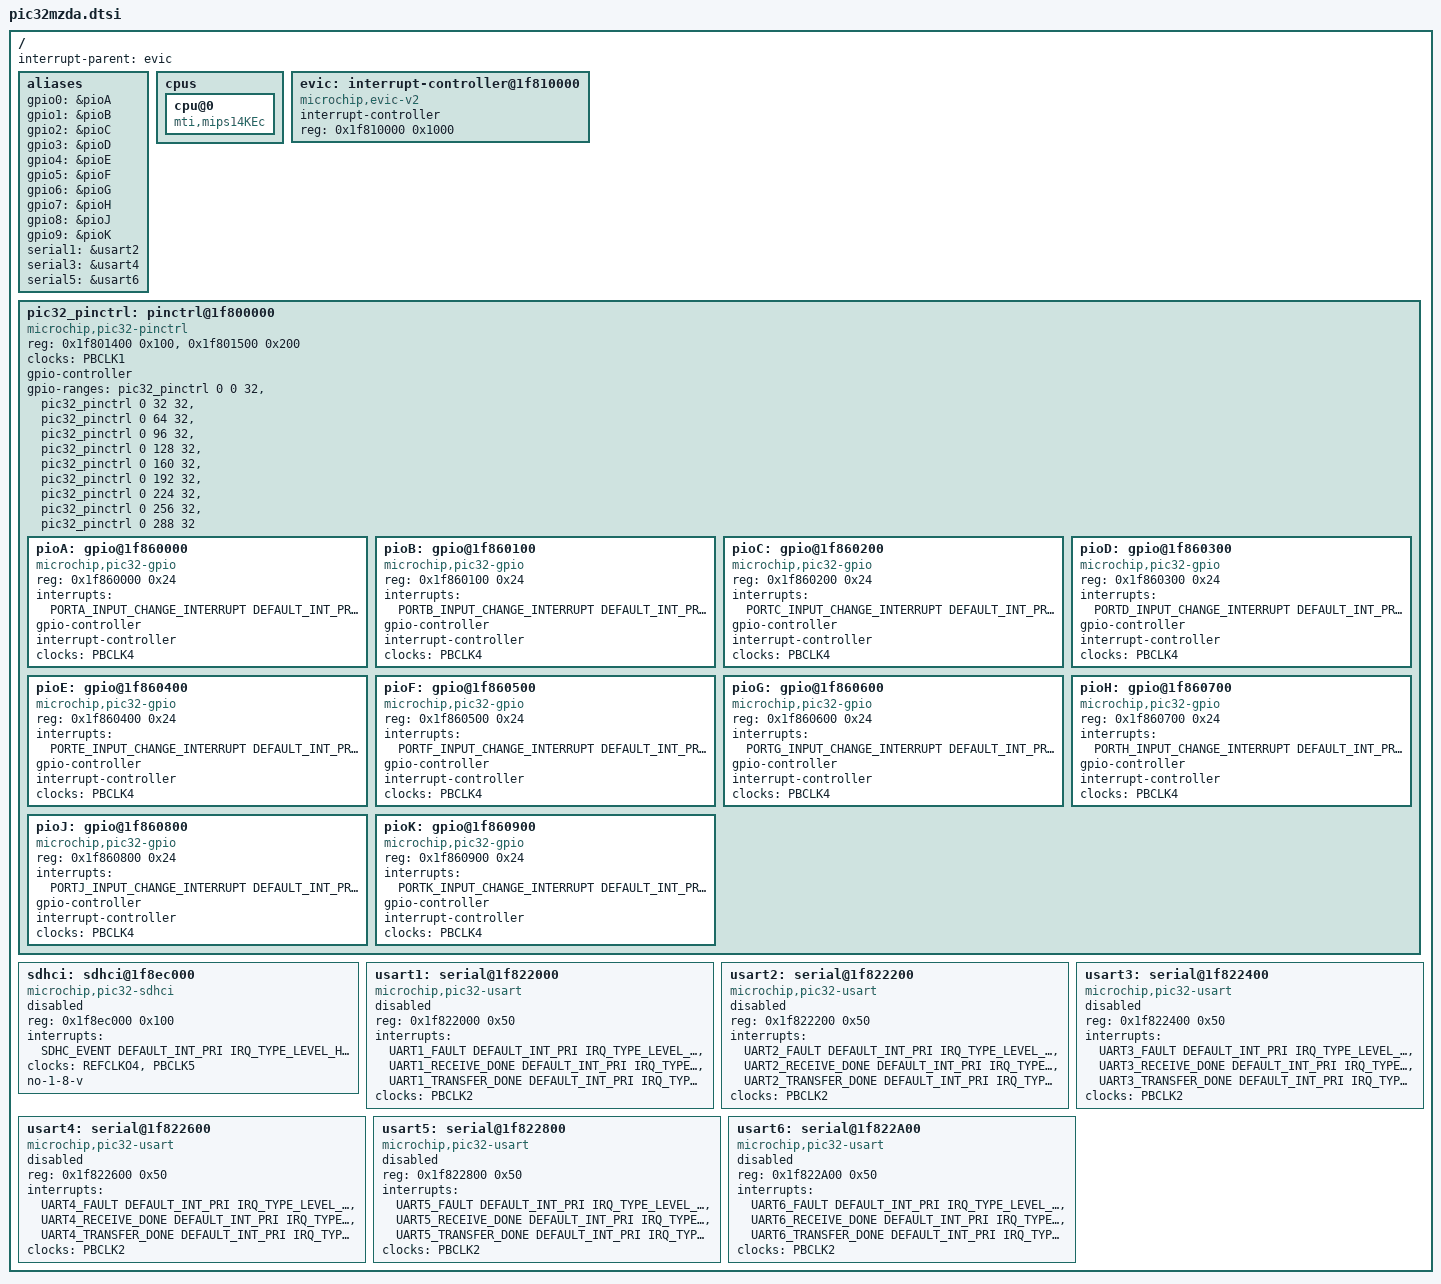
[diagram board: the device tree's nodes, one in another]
/*
 * Copyright (C) 2015 Microchip Technology Inc.  All rights reserved.
 *
 * This program is free software; you can redistribute it and/or modify
 * it under the terms of the GNU General Public License version 2 as
 * published by the Free Software Foundation.
 *
 */

#include <dt-bindings/interrupt-controller/microchip,pic32mz-evic.h>

#include "pic32mzda-clk.dtsi"

/ {
	#address-cells = <1>;
	#size-cells = <1>;
	interrupt-parent = <&evic>;

	aliases {
		gpio0 = &pioA;
		gpio1 = &pioB;
		gpio2 = &pioC;
		gpio3 = &pioD;
		gpio4 = &pioE;
		gpio5 = &pioF;
		gpio6 = &pioG;
		gpio7 = &pioH;
		gpio8 = &pioJ;
		gpio9 = &pioK;
		serial1 = &usart2;
		serial3 = &usart4;
		serial5 = &usart6;
	};

	cpus {
		#address-cells = <1>;
		#size-cells = <0>;

		cpu@0 {
			compatible = "mti,mips14KEc";
			device_type = "cpu";
		};
	};

	evic: interrupt-controller@1f810000 {
		compatible = "microchip,evic-v2";
		interrupt-controller;
		#interrupt-cells = <3>;
		reg = <0x1f810000 0x1000>;
		device_type="evic-v2";
	};

	pic32_pinctrl: pinctrl@1f800000{
		#address-cells = <1>;
		#size-cells = <1>;
		#gpio-range-cells = <3>;
		compatible = "microchip,pic32-pinctrl", "simple-bus";
		ranges;
		reg = <0x1f801400 0x100>, /* in	 */
		      <0x1f801500 0x200>; /* out */
		clocks = <&PBCLK1>;
		gpio-controller;
		#gpio-cells = <2>;
		gpio-ranges = <&pic32_pinctrl 0 0 32
			&pic32_pinctrl 0 32 32
			&pic32_pinctrl 0 64 32
			&pic32_pinctrl 0 96 32
			&pic32_pinctrl 0 128 32
			&pic32_pinctrl 0 160 32
			&pic32_pinctrl 0 192 32
			&pic32_pinctrl 0 224 32
			&pic32_pinctrl 0 256 32
			&pic32_pinctrl 0 288 32>;

		/* GPIO banks */
		pioA: gpio@1f860000 {
			compatible = "microchip,pic32-gpio";
			reg = <0x1f860000 0x24>;
			interrupts = <PORTA_INPUT_CHANGE_INTERRUPT
					DEFAULT_INT_PRI IRQ_TYPE_LEVEL_HIGH>;
			#gpio-cells = <2>;
			gpio-controller;
			interrupt-controller;
			#interrupt-cells = <2>;
			clocks = <&PBCLK4>;
		};

		pioB: gpio@1f860100 {
			compatible = "microchip,pic32-gpio";
			reg = <0x1f860100 0x24>;
			interrupts = <PORTB_INPUT_CHANGE_INTERRUPT
					DEFAULT_INT_PRI IRQ_TYPE_LEVEL_HIGH>;
			#gpio-cells = <2>;
			gpio-controller;
			interrupt-controller;
			#interrupt-cells = <2>;
			clocks = <&PBCLK4>;
		};

		pioC: gpio@1f860200 {
			compatible = "microchip,pic32-gpio";
			reg = <0x1f860200 0x24>;
			interrupts = <PORTC_INPUT_CHANGE_INTERRUPT
					DEFAULT_INT_PRI IRQ_TYPE_LEVEL_HIGH>;
			#gpio-cells = <2>;
			gpio-controller;
			interrupt-controller;
			#interrupt-cells = <2>;
			clocks = <&PBCLK4>;
		};

		pioD: gpio@1f860300 {
			compatible = "microchip,pic32-gpio";
			reg = <0x1f860300 0x24>;
			interrupts = <PORTD_INPUT_CHANGE_INTERRUPT
					DEFAULT_INT_PRI IRQ_TYPE_LEVEL_HIGH>;
			#gpio-cells = <2>;
			gpio-controller;
			interrupt-controller;
			#interrupt-cells = <2>;
			clocks = <&PBCLK4>;
		};

		pioE: gpio@1f860400 {
			compatible = "microchip,pic32-gpio";
			reg = <0x1f860400 0x24>;
			interrupts = <PORTE_INPUT_CHANGE_INTERRUPT
					DEFAULT_INT_PRI IRQ_TYPE_LEVEL_HIGH>;
			#gpio-cells = <2>;
			gpio-controller;
			interrupt-controller;
			#interrupt-cells = <2>;
			clocks = <&PBCLK4>;
		};

		pioF: gpio@1f860500 {
			compatible = "microchip,pic32-gpio";
			reg = <0x1f860500 0x24>;
			interrupts = <PORTF_INPUT_CHANGE_INTERRUPT
					DEFAULT_INT_PRI IRQ_TYPE_LEVEL_HIGH>;
			#gpio-cells = <2>;
			gpio-controller;
			interrupt-controller;
			#interrupt-cells = <2>;
			clocks = <&PBCLK4>;
		};

		pioG: gpio@1f860600 {
			compatible = "microchip,pic32-gpio";
			reg = <0x1f860600 0x24>;
			interrupts = <PORTG_INPUT_CHANGE_INTERRUPT
					 DEFAULT_INT_PRI IRQ_TYPE_LEVEL_HIGH>;
			#gpio-cells = <2>;
			gpio-controller;
			interrupt-controller;
			#interrupt-cells = <2>;
			clocks = <&PBCLK4>;
		};

		pioH: gpio@1f860700 {
			compatible = "microchip,pic32-gpio";
			reg = <0x1f860700 0x24>;
			interrupts = <PORTH_INPUT_CHANGE_INTERRUPT
					DEFAULT_INT_PRI IRQ_TYPE_LEVEL_HIGH>;
			#gpio-cells = <2>;
			gpio-controller;
			interrupt-controller;
			#interrupt-cells = <2>;
			clocks = <&PBCLK4>;
		};

		/* There is no pioI */

		pioJ: gpio@1f860800 {
			compatible = "microchip,pic32-gpio";
			reg = <0x1f860800 0x24>;
			interrupts = <PORTJ_INPUT_CHANGE_INTERRUPT
					DEFAULT_INT_PRI IRQ_TYPE_LEVEL_HIGH>;
			#gpio-cells = <2>;
			gpio-controller;
			interrupt-controller;
			#interrupt-cells = <2>;
			clocks = <&PBCLK4>;
		};

		pioK: gpio@1f860900 {
			compatible = "microchip,pic32-gpio";
			reg = <0x1f860900 0x24>;
			interrupts = <PORTK_INPUT_CHANGE_INTERRUPT
					DEFAULT_INT_PRI IRQ_TYPE_LEVEL_HIGH>;
			#gpio-cells = <2>;
			gpio-controller;
			interrupt-controller;
			#interrupt-cells = <2>;
			clocks = <&PBCLK4>;
		};
	};

	sdhci: sdhci@1f8ec000 {
		compatible = "microchip,pic32-sdhci";
		reg = <0x1f8ec000 0x100>;
		interrupts = <SDHC_EVENT DEFAULT_INT_PRI IRQ_TYPE_LEVEL_HIGH>;
		clocks = <&REFCLKO4>, <&PBCLK5>;
		clock-names = "base_clk", "sys_clk";
		no-1-8-v;
		status = "disabled";
	};

	usart1: serial@1f822000 {
		compatible = "microchip,pic32-usart";
		reg = <0x1f822000 0x50>;
		interrupts = <UART1_FAULT DEFAULT_INT_PRI IRQ_TYPE_LEVEL_HIGH>,
			<UART1_RECEIVE_DONE DEFAULT_INT_PRI
				IRQ_TYPE_LEVEL_HIGH>,
			<UART1_TRANSFER_DONE DEFAULT_INT_PRI
				IRQ_TYPE_LEVEL_HIGH>;
		clocks = <&PBCLK2>;
		status = "disabled";
	};

	usart2: serial@1f822200 {
		compatible = "microchip,pic32-usart";
		reg = <0x1f822200 0x50>;
		interrupts = <UART2_FAULT DEFAULT_INT_PRI IRQ_TYPE_LEVEL_HIGH>,
			<UART2_RECEIVE_DONE DEFAULT_INT_PRI
				IRQ_TYPE_LEVEL_HIGH>,
			<UART2_TRANSFER_DONE DEFAULT_INT_PRI
				IRQ_TYPE_LEVEL_HIGH>;
		clocks = <&PBCLK2>;
		status = "disabled";
	};

	usart3: serial@1f822400 {
		compatible = "microchip,pic32-usart";
		reg = <0x1f822400 0x50>;
		interrupts = <UART3_FAULT DEFAULT_INT_PRI IRQ_TYPE_LEVEL_HIGH>,
			<UART3_RECEIVE_DONE DEFAULT_INT_PRI
				IRQ_TYPE_LEVEL_HIGH>,
			<UART3_TRANSFER_DONE DEFAULT_INT_PRI
				IRQ_TYPE_LEVEL_HIGH>;
		clocks = <&PBCLK2>;
		status = "disabled";
	};

	usart4: serial@1f822600 {
		compatible = "microchip,pic32-usart";
		reg = <0x1f822600 0x50>;
		interrupts = <UART4_FAULT DEFAULT_INT_PRI IRQ_TYPE_LEVEL_HIGH>,
			<UART4_RECEIVE_DONE DEFAULT_INT_PRI
				IRQ_TYPE_LEVEL_HIGH>,
			<UART4_TRANSFER_DONE DEFAULT_INT_PRI
				IRQ_TYPE_LEVEL_HIGH>;
		clocks = <&PBCLK2>;
		status = "disabled";
	};

	usart5: serial@1f822800 {
		compatible = "microchip,pic32-usart";
		reg = <0x1f822800 0x50>;
		interrupts = <UART5_FAULT DEFAULT_INT_PRI IRQ_TYPE_LEVEL_HIGH>,
			<UART5_RECEIVE_DONE DEFAULT_INT_PRI
				IRQ_TYPE_LEVEL_HIGH>,
			<UART5_TRANSFER_DONE DEFAULT_INT_PRI
				IRQ_TYPE_LEVEL_HIGH>;
		clocks = <&PBCLK2>;
		status = "disabled";
	};

	usart6: serial@1f822A00 {
		compatible = "microchip,pic32-usart";
		reg = <0x1f822A00 0x50>;
		interrupts = <UART6_FAULT DEFAULT_INT_PRI IRQ_TYPE_LEVEL_HIGH>,
			<UART6_RECEIVE_DONE DEFAULT_INT_PRI
				IRQ_TYPE_LEVEL_HIGH>,
			<UART6_TRANSFER_DONE DEFAULT_INT_PRI
				IRQ_TYPE_LEVEL_HIGH>;
		clocks = <&PBCLK2>;
		status = "disabled";
	};
};
